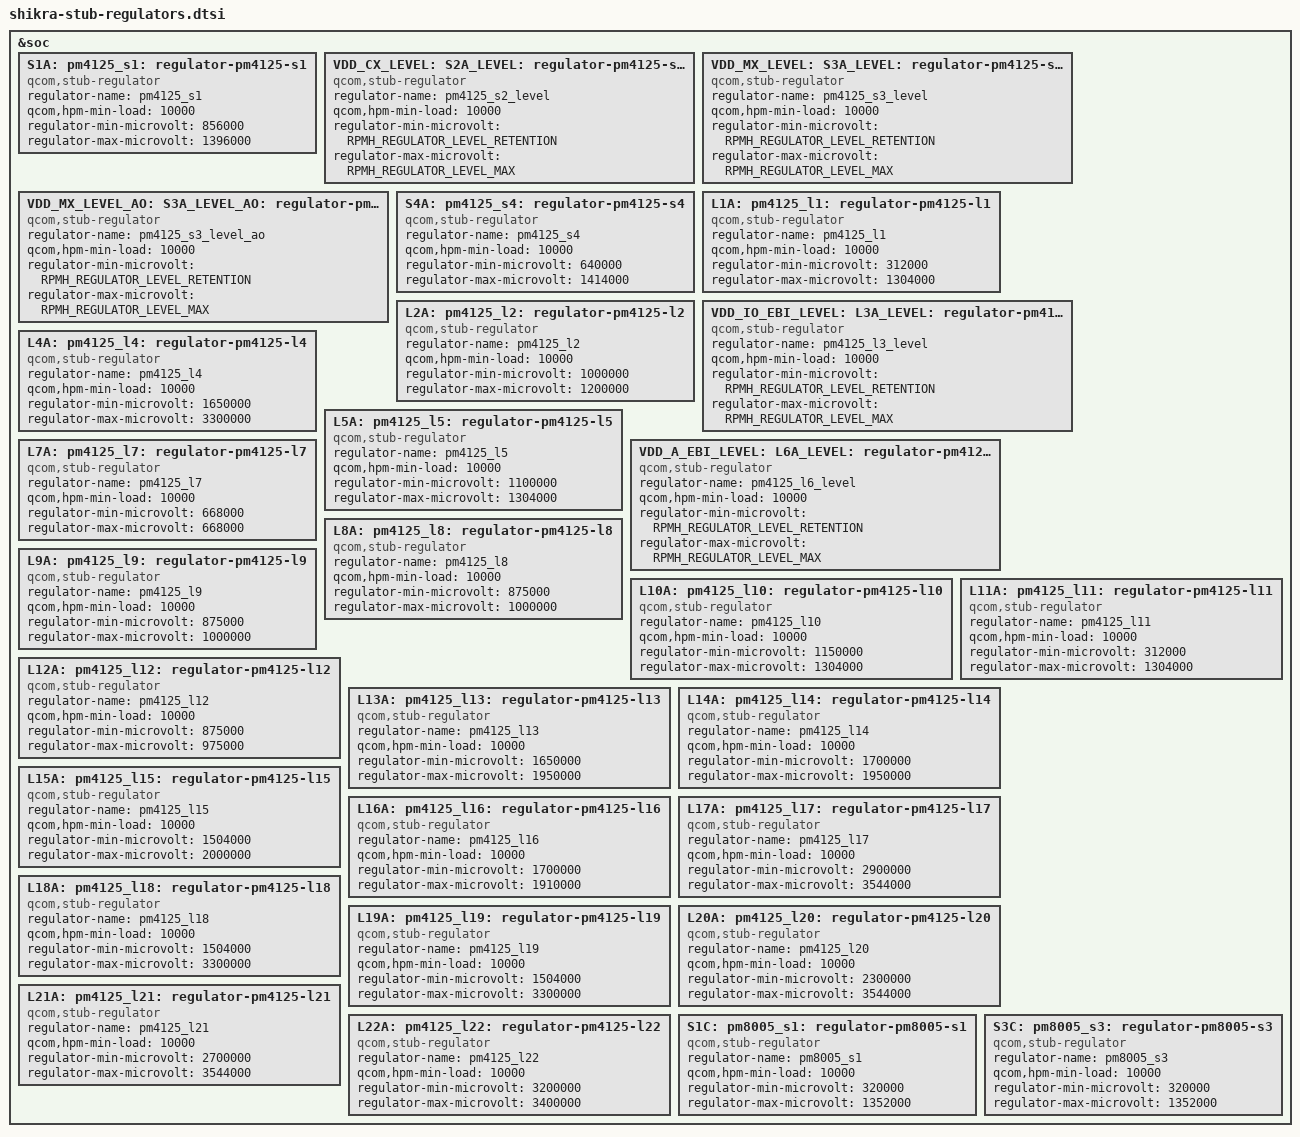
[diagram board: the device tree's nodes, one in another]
// SPDX-License-Identifier: BSD-3-Clause
/*
 * Copyright (c) Qualcomm Technologies, Inc. and/or its subsidiaries.
 */

#include <dt-bindings/regulator/qcom,rpmh-regulator-levels.h>

&soc {
		S1A:
		pm4125_s1: regulator-pm4125-s1 {
			compatible = "qcom,stub-regulator";
			regulator-name = "pm4125_s1";
			qcom,hpm-min-load = <10000>;
			regulator-min-microvolt = <856000>;
			regulator-max-microvolt = <1396000>;
		};

		VDD_CX_LEVEL:
		S2A_LEVEL:
		pm4125_s2_level: regulator-pm4125-s2-level {
			compatible = "qcom,stub-regulator";
			regulator-name = "pm4125_s2_level";
			qcom,hpm-min-load = <10000>;
			regulator-min-microvolt =
				<RPMH_REGULATOR_LEVEL_RETENTION>;
			regulator-max-microvolt = <RPMH_REGULATOR_LEVEL_MAX>;
		};

		VDD_MX_LEVEL:
		S3A_LEVEL:
		pm4125_s3_level: regulator-pm4125-s3-level {
			compatible = "qcom,stub-regulator";
			regulator-name = "pm4125_s3_level";
			qcom,hpm-min-load = <10000>;
			regulator-min-microvolt =
				<RPMH_REGULATOR_LEVEL_RETENTION>;
			regulator-max-microvolt = <RPMH_REGULATOR_LEVEL_MAX>;
		};

		VDD_MX_LEVEL_AO:
		S3A_LEVEL_AO:
		pm4125_s3_level_ao: regulator-pm4125-s3-level-ao {
			compatible = "qcom,stub-regulator";
			regulator-name = "pm4125_s3_level_ao";
			qcom,hpm-min-load = <10000>;
			regulator-min-microvolt =
				<RPMH_REGULATOR_LEVEL_RETENTION>;
			regulator-max-microvolt = <RPMH_REGULATOR_LEVEL_MAX>;
		};

		S4A:
		pm4125_s4: regulator-pm4125-s4 {
			compatible = "qcom,stub-regulator";
			regulator-name = "pm4125_s4";
			qcom,hpm-min-load = <10000>;
			regulator-min-microvolt = <640000>;
			regulator-max-microvolt = <1414000>;
		};

		L1A:
		pm4125_l1: regulator-pm4125-l1 {
			compatible = "qcom,stub-regulator";
			regulator-name = "pm4125_l1";
			qcom,hpm-min-load = <10000>;
			regulator-min-microvolt = <312000>;
			regulator-max-microvolt = <1304000>;
		};

		L2A:
		pm4125_l2: regulator-pm4125-l2 {
			compatible = "qcom,stub-regulator";
			regulator-name = "pm4125_l2";
			qcom,hpm-min-load = <10000>;
			regulator-min-microvolt = <1000000>;
			regulator-max-microvolt = <1200000>;
		};

		VDD_IO_EBI_LEVEL:
		L3A_LEVEL:
		pm4125_l3_level: regulator-pm4125-l3-level {
			compatible = "qcom,stub-regulator";
			regulator-name = "pm4125_l3_level";
			qcom,hpm-min-load = <10000>;
			regulator-min-microvolt =
				<RPMH_REGULATOR_LEVEL_RETENTION>;
			regulator-max-microvolt = <RPMH_REGULATOR_LEVEL_MAX>;
		};

		L4A:
		pm4125_l4: regulator-pm4125-l4 {
			compatible = "qcom,stub-regulator";
			regulator-name = "pm4125_l4";
			qcom,hpm-min-load = <10000>;
			regulator-min-microvolt = <1650000>;
			regulator-max-microvolt = <3300000>;
		};

		L5A:
		pm4125_l5: regulator-pm4125-l5 {
			compatible = "qcom,stub-regulator";
			regulator-name = "pm4125_l5";
			qcom,hpm-min-load = <10000>;
			regulator-min-microvolt = <1100000>;
			regulator-max-microvolt = <1304000>;
		};

		VDD_A_EBI_LEVEL:
		L6A_LEVEL:
		pm4125_l6_level: regulator-pm4125-l6-level {
			compatible = "qcom,stub-regulator";
			regulator-name = "pm4125_l6_level";
			qcom,hpm-min-load = <10000>;
			regulator-min-microvolt =
				<RPMH_REGULATOR_LEVEL_RETENTION>;
			regulator-max-microvolt = <RPMH_REGULATOR_LEVEL_MAX>;
		};

		L7A:
		pm4125_l7: regulator-pm4125-l7 {
			compatible = "qcom,stub-regulator";
			regulator-name = "pm4125_l7";
			qcom,hpm-min-load = <10000>;
			regulator-min-microvolt = <668000>;
			regulator-max-microvolt = <668000>;
		};

		L8A:
		pm4125_l8: regulator-pm4125-l8 {
			compatible = "qcom,stub-regulator";
			regulator-name = "pm4125_l8";
			qcom,hpm-min-load = <10000>;
			regulator-min-microvolt = <875000>;
			regulator-max-microvolt = <1000000>;
		};

		L9A:
		pm4125_l9: regulator-pm4125-l9 {
			compatible = "qcom,stub-regulator";
			regulator-name = "pm4125_l9";
			qcom,hpm-min-load = <10000>;
			regulator-min-microvolt = <875000>;
			regulator-max-microvolt = <1000000>;
		};

		L10A:
		pm4125_l10: regulator-pm4125-l10 {
			compatible = "qcom,stub-regulator";
			regulator-name = "pm4125_l10";
			qcom,hpm-min-load = <10000>;
			regulator-min-microvolt = <1150000>;
			regulator-max-microvolt = <1304000>;
		};

		L11A:
		pm4125_l11: regulator-pm4125-l11 {
			compatible = "qcom,stub-regulator";
			regulator-name = "pm4125_l11";
			qcom,hpm-min-load = <10000>;
			regulator-min-microvolt = <312000>;
			regulator-max-microvolt = <1304000>;
		};

		L12A:
		pm4125_l12: regulator-pm4125-l12 {
			compatible = "qcom,stub-regulator";
			regulator-name = "pm4125_l12";
			qcom,hpm-min-load = <10000>;
			regulator-min-microvolt = <875000>;
			regulator-max-microvolt = <975000>;
		};

		L13A:
		pm4125_l13: regulator-pm4125-l13 {
			compatible = "qcom,stub-regulator";
			regulator-name = "pm4125_l13";
			qcom,hpm-min-load = <10000>;
			regulator-min-microvolt = <1650000>;
			regulator-max-microvolt = <1950000>;
		};

		L14A:
		pm4125_l14: regulator-pm4125-l14 {
			compatible = "qcom,stub-regulator";
			regulator-name = "pm4125_l14";
			qcom,hpm-min-load = <10000>;
			regulator-min-microvolt = <1700000>;
			regulator-max-microvolt = <1950000>;
		};

		L15A:
		pm4125_l15: regulator-pm4125-l15 {
			compatible = "qcom,stub-regulator";
			regulator-name = "pm4125_l15";
			qcom,hpm-min-load = <10000>;
			regulator-min-microvolt = <1504000>;
			regulator-max-microvolt = <2000000>;
		};

		L16A:
		pm4125_l16: regulator-pm4125-l16 {
			compatible = "qcom,stub-regulator";
			regulator-name = "pm4125_l16";
			qcom,hpm-min-load = <10000>;
			regulator-min-microvolt = <1700000>;
			regulator-max-microvolt = <1910000>;
		};

		L17A:
		pm4125_l17: regulator-pm4125-l17 {
			compatible = "qcom,stub-regulator";
			regulator-name = "pm4125_l17";
			qcom,hpm-min-load = <10000>;
			regulator-min-microvolt = <2900000>;
			regulator-max-microvolt = <3544000>;
		};

		L18A:
		pm4125_l18: regulator-pm4125-l18 {
			compatible = "qcom,stub-regulator";
			regulator-name = "pm4125_l18";
			qcom,hpm-min-load = <10000>;
			regulator-min-microvolt = <1504000>;
			regulator-max-microvolt = <3300000>;
		};

		L19A:
		pm4125_l19: regulator-pm4125-l19 {
			compatible = "qcom,stub-regulator";
			regulator-name = "pm4125_l19";
			qcom,hpm-min-load = <10000>;
			regulator-min-microvolt = <1504000>;
			regulator-max-microvolt = <3300000>;
		};

		L20A:
		pm4125_l20: regulator-pm4125-l20 {
			compatible = "qcom,stub-regulator";
			regulator-name = "pm4125_l20";
			qcom,hpm-min-load = <10000>;
			regulator-min-microvolt = <2300000>;
			regulator-max-microvolt = <3544000>;
		};

		L21A:
		pm4125_l21: regulator-pm4125-l21 {
			compatible = "qcom,stub-regulator";
			regulator-name = "pm4125_l21";
			qcom,hpm-min-load = <10000>;
			regulator-min-microvolt = <2700000>;
			regulator-max-microvolt = <3544000>;
		};

		L22A:
		pm4125_l22: regulator-pm4125-l22 {
			compatible = "qcom,stub-regulator";
			regulator-name = "pm4125_l22";
			qcom,hpm-min-load = <10000>;
			regulator-min-microvolt = <3200000>;
			regulator-max-microvolt = <3400000>;
		};

		S1C:
		pm8005_s1: regulator-pm8005-s1 {
			compatible = "qcom,stub-regulator";
			regulator-name = "pm8005_s1";
			qcom,hpm-min-load = <10000>;
			regulator-min-microvolt = <320000>;
			regulator-max-microvolt = <1352000>;
		};

		S3C:
		pm8005_s3: regulator-pm8005-s3 {
			compatible = "qcom,stub-regulator";
			regulator-name = "pm8005_s3";
			qcom,hpm-min-load = <10000>;
			regulator-min-microvolt = <320000>;
			regulator-max-microvolt = <1352000>;
		};
};
